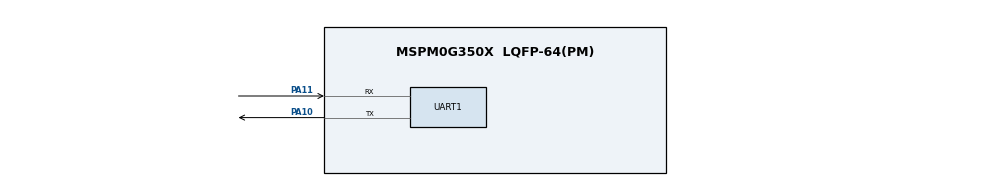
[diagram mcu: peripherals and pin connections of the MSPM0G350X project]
/**
 * @cliArgs --device "MSPM0G350X" --package "LQFP-64(PM)" --part "Default" --product "mspm0_sdk@2.01.00.03"
 * @versions {"tool":"1.20.0+3587"}
 */

/**
 * Import the modules used in this configuration.
 */
const GPIO    = scripting.addModule("/ti/driverlib/GPIO", {}, false);
const GPIO1   = GPIO.addInstance();
const GPIO2   = GPIO.addInstance();
const GPIO3   = GPIO.addInstance();
const GPIO4   = GPIO.addInstance();
const GPIO5   = GPIO.addInstance();
const SYSCTL  = scripting.addModule("/ti/driverlib/SYSCTL");
const SYSTICK = scripting.addModule("/ti/driverlib/SYSTICK");
const UART    = scripting.addModule("/ti/driverlib/UART", {}, false);
const UART1   = UART.addInstance();

/**
 * Write custom configuration values to the imported modules.
 */
const divider7       = system.clockTree["PLL_PDIV"];
divider7.divideValue = 2;

const divider9       = system.clockTree["UDIV"];
divider9.divideValue = 2;

const gate7  = system.clockTree["MFCLKGATE"];
gate7.enable = true;

const multiplier2         = system.clockTree["PLL_QDIV"];
multiplier2.multiplyValue = 5;

const mux8       = system.clockTree["HSCLKMUX"];
mux8.inputSelect = "HSCLKMUX_SYSPLL2X";

GPIO1.$name                              = "LED1";
GPIO1.port                               = "PORTB";
GPIO1.associatedPins[0].$name            = "PIN_0";
GPIO1.associatedPins[0].internalResistor = "PULL_DOWN";
GPIO1.associatedPins[0].assignedPin      = "9";

const Board = scripting.addModule("/ti/driverlib/Board", {}, false);

GPIO2.port                          = "PORTB";
GPIO2.$name                         = "IR_DH4";
GPIO2.associatedPins[0].direction   = "INPUT";
GPIO2.associatedPins[0].assignedPin = "17";
GPIO2.associatedPins[0].$name       = "PIN_17";

GPIO3.port                          = "PORTB";
GPIO3.$name                         = "IR_DH3";
GPIO3.associatedPins[0].$name       = "PIN_16";
GPIO3.associatedPins[0].assignedPin = "16";
GPIO3.associatedPins[0].direction   = "INPUT";

GPIO4.port                          = "PORTA";
GPIO4.$name                         = "IR_DH2";
GPIO4.associatedPins[0].assignedPin = "12";
GPIO4.associatedPins[0].direction   = "INPUT";
GPIO4.associatedPins[0].$name       = "PIN_12";

GPIO5.port                          = "PORTA";
GPIO5.$name                         = "IR_DH1";
GPIO5.associatedPins[0].assignedPin = "27";
GPIO5.associatedPins[0].$name       = "PIN_27";
GPIO5.associatedPins[0].direction   = "INPUT";

SYSCTL.forceDefaultClkConfig = true;
SYSCTL.clockTreeEn           = true;

SYSTICK.periodEnable      = true;
SYSTICK.systickEnable     = true;
SYSTICK.interruptPriority = "0";
SYSTICK.period            = 16777162;

UART1.$name                    = "UART_0";
UART1.enabledInterrupts        = ["RX"];
UART1.uartClkSrc               = "MFCLK";
UART1.peripheral.$assign       = "UART0";
UART1.peripheral.rxPin.$assign = "PA11";
UART1.peripheral.txPin.$assign = "PA10";
UART1.txPinConfig.$name        = "ti_driverlib_gpio_GPIOPinGeneric0";
UART1.rxPinConfig.$name        = "ti_driverlib_gpio_GPIOPinGeneric1";

/**
 * Pinmux solution for unlocked pins/peripherals. This ensures that minor changes to the automatic solver in a future
 * version of the tool will not impact the pinmux you originally saw.  These lines can be completely deleted in order to
 * re-solve from scratch.
 */
GPIO1.associatedPins[0].pin.$suggestSolution = "PB9";
Board.peripheral.$suggestSolution            = "DEBUGSS";
Board.peripheral.swclkPin.$suggestSolution   = "PA20";
Board.peripheral.swdioPin.$suggestSolution   = "PA19";
GPIO2.associatedPins[0].pin.$suggestSolution = "PB17";
GPIO3.associatedPins[0].pin.$suggestSolution = "PB16";
GPIO4.associatedPins[0].pin.$suggestSolution = "PA12";
GPIO5.associatedPins[0].pin.$suggestSolution = "PA27";
